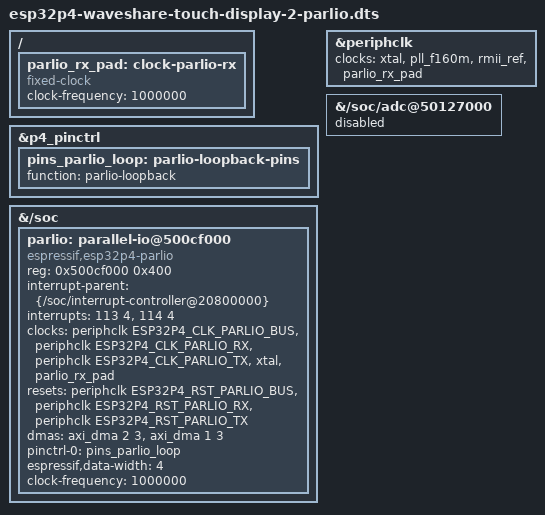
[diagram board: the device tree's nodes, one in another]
// SPDX-License-Identifier: (GPL-2.0-only OR BSD-2-Clause)
#include "esp32p4-waveshare-touch-display-2.dts"

/ {
	/* The loopback routes the configured TX clock to the receiver pad. */
	parlio_rx_pad: clock-parlio-rx {
		compatible = "fixed-clock";
		#clock-cells = <0>;
		clock-frequency = <1000000>;
	};
};

&p4_pinctrl {
	pins_parlio_loop: parlio-loopback-pins {
		function = "parlio-loopback";
	};
};

&periphclk {
	clocks = <&xtal>, <&pll_f160m>, <&rmii_ref>, <&parlio_rx_pad>;
};

&{/soc} {
	/* P4 v1.3 TRM ch.56 PARLIO, ch.4 AXI GDMA peripheral selector 3. */
	parlio: parallel-io@500cf000 {
		compatible = "espressif,esp32p4-parlio";
		reg = <0x500cf000 0x400>;
		interrupt-parent = <&{/soc/interrupt-controller@20800000}>;
		interrupts = <113 4>, <114 4>;
		interrupt-names = "rx", "tx";
		clocks = <&periphclk ESP32P4_CLK_PARLIO_BUS>,
			 <&periphclk ESP32P4_CLK_PARLIO_RX>,
			 <&periphclk ESP32P4_CLK_PARLIO_TX>,
			 <&xtal>, <&parlio_rx_pad>;
		clock-names = "bus", "rx", "tx", "xtal", "rx-pad";
		resets = <&periphclk ESP32P4_RST_PARLIO_BUS>,
			 <&periphclk ESP32P4_RST_PARLIO_RX>,
			 <&periphclk ESP32P4_RST_PARLIO_TX>;
		reset-names = "bus", "rx", "tx";
		dmas = <&axi_dma 2 3>, <&axi_dma 1 3>;
		dma-names = "rx", "tx";
		pinctrl-names = "default";
		pinctrl-0 = <&pins_parlio_loop>;
		espressif,data-width = <4>;
		clock-frequency = <1000000>;
	};
};

/* The loopback takes GPIO20 and GPIO21 from the ADC header group. */
&{/soc/adc@50127000} {
	status = "disabled";
};
